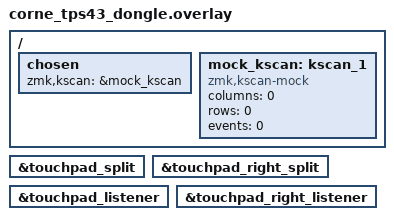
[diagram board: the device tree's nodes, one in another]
#include "corne_tps43.dtsi"

/ {
    chosen {
        zmk,kscan = &mock_kscan;
    };

    mock_kscan: kscan_1 {
        compatible = "zmk,kscan-mock";
        columns = <0>;
        rows = <0>;
        events = <0>;
    };
};

&touchpad_split {
    status = "okay";
};

&touchpad_right_split {
    status = "okay";
};

&touchpad_listener {
    status = "okay";
};

&touchpad_right_listener {
    status = "okay";
};
